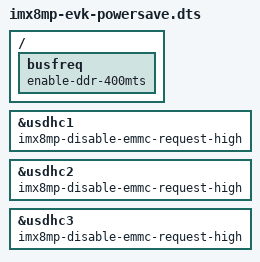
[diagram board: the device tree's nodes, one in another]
// SPDX-License-Identifier: (GPL-2.0+ OR MIT)
/*
 * Copyright 2019 NXP
 */

#include "imx8mp-evk-rpmsg.dts"

&usdhc1 {
	imx8mp-disable-emmc-request-high;
};

&usdhc2 {
	imx8mp-disable-emmc-request-high;
};

&usdhc3 {
	imx8mp-disable-emmc-request-high;
};

/ {
  busfreq {
	enable-ddr-400mts;
  };
};
